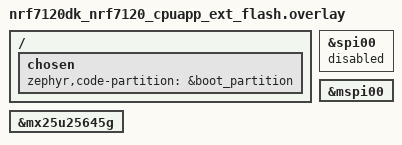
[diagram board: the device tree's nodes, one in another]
/*
 * Copyright (c) 2026 Nordic Semiconductor ASA
 *
 * SPDX-License-Identifier: LicenseRef-Nordic-5-Clause
 */

#include "../../../dts/nrf7120dk_nrf7120_memory_map_ext_flash.dtsi"

/ {
	chosen {
		zephyr,code-partition = &boot_partition;
	};
};

&spi00 {
	status = "disabled";
};

&mspi00 {
	status = "okay";
};

&mx25u25645g {
	status = "okay";
};
